# STM32N657 register map
File version: 1.0
CPU: CM55 r0p1, little endian, no MPU, FPU, vendor SysTick, 8 interrupt priority bits
Registers are 32-bit, read-write, reset 0x0 unless marked. A register's access mark holds for its fields unless they carry their own. Offsets are from the block's base; [hi:lo] are bit positions; {n}, {i} and the like mark numbered series.

## TIM1 — Advanced-control timers
Base 0x42000000
Same registers: TIM1_S 0x52000000
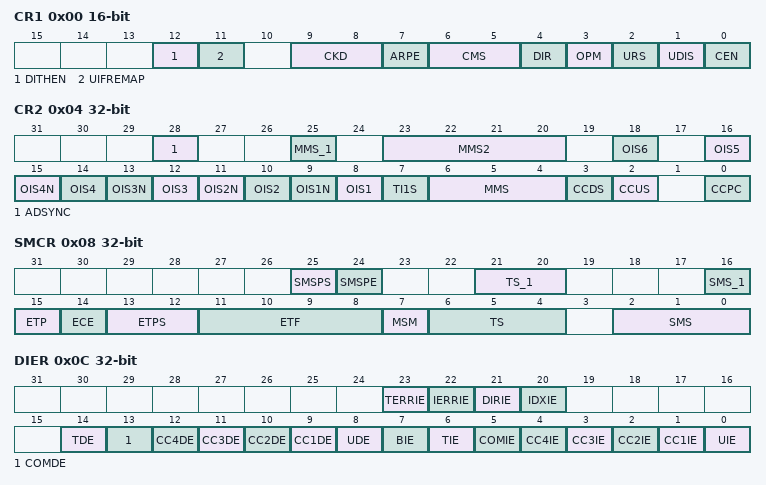
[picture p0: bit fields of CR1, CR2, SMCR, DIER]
0x00 CR1 16-bit — TIM1 control register 1
  [12] DITHEN — Dithering enable
  [11] UIFREMAP — UIF status bit remapping
  [9:8] CKD — Clock division
  [7] ARPE — Auto-reload preload enable
  [6:5] CMS — Center-aligned mode selection
  [4] DIR — Direction
  [3] OPM — One-pulse mode
  [2] URS — Update request source
  [1] UDIS — Update disable
  [0] CEN — Counter enable
0x04 CR2 — TIM1 control register 2
  [28] ADSYNC — ADC synchronization
  [25] MMS_1 — MMS[3]
  [23:20] MMS2 — Master mode selection 2
  [18] OIS6 — Output idle state 6 (tim_oc6 output)
  [16] OIS5 — Output idle state 5 (tim_oc5 output)
  [2n+7] OIS{n}N (n=1..4) — Output idle state {n} (tim_oc{n}n output)
  [14] OIS4 — Output idle state 4 (tim_oc4 output)
  [12] OIS3 — Output idle state 3 (tim_oc3n output)
  [10] OIS2 — Output idle state 2 (tim_oc2 output)
  [8] OIS1 — Output idle state 1 (tim_oc1 output)
  [7] TI1S — tim_ti1 selection
  [6:4] MMS — MMS[2:0]: Master mode selection
  [3] CCDS — Capture/compare DMA selection
  [2] CCUS — Capture/compare control update selection
  [0] CCPC — Capture/compare preloaded control
0x08 SMCR — TIM1 slave mode control register
  [25] SMSPS — SMS preload source
  [24] SMSPE — SMS preload enable
  [21:20] TS_1 — TS[4:3]
  [16] SMS_1 — SMS[3]
  [15] ETP — External trigger polarity
  [14] ECE — External clock enable
  [13:12] ETPS — External trigger prescaler
  [11:8] ETF — External trigger filter
  [7] MSM — Master/slave mode
  [6:4] TS — TS[2:0]: Trigger selection
  [2:0] SMS — SMS[2:0]: Slave mode selection
0x0C DIER — TIM1 DMA/interrupt enable register
  [23] TERRIE — Transition error interrupt enable
  [22] IERRIE — Index error interrupt enable
  [21] DIRIE — Direction change interrupt enable
  [20] IDXIE — Index interrupt enable
  [14] TDE — Trigger DMA request enable
  [13] COMDE — COM DMA request enable
  [n+8] CC{n}DE (n=1..4) — Capture/compare {n} DMA request enable
  [8] UDE — Update DMA request enable
  [7] BIE — Break interrupt enable
  [6] TIE — Trigger interrupt enable
  [5] COMIE — COM interrupt enable
  [n] CC{n}IE (n=1..4) — Capture/compare {n} interrupt enable
  [0] UIE — Update interrupt enable
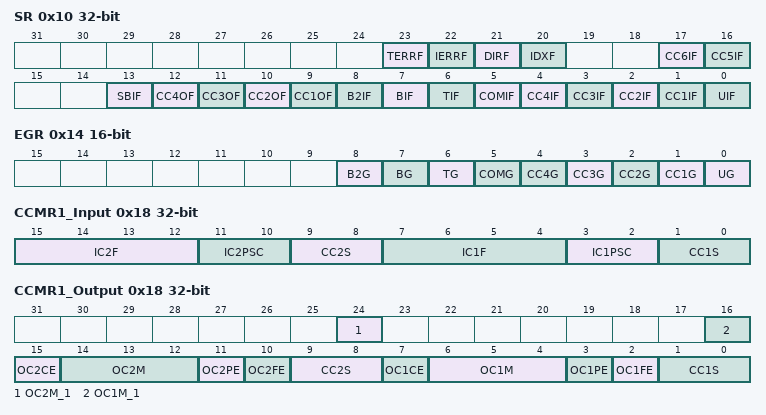
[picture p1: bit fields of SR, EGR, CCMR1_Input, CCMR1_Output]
0x10 SR — TIM1 status register
  [23] TERRF — Transition error interrupt flag
  [22] IERRF — Index error interrupt flag
  [21] DIRF — Direction change interrupt flag
  [20] IDXF — Index interrupt flag
  [17] CC6IF — Compare 6 interrupt flag
  [16] CC5IF — Compare 5 interrupt flag
  [13] SBIF — System break interrupt flag
  [n+8] CC{n}OF (n=1..4) — Capture/compare {n} overcapture flag
  [8] B2IF — Break 2 interrupt flag
  [7] BIF — Break interrupt flag
  [6] TIF — Trigger interrupt flag
  [5] COMIF — COM interrupt flag
  [n] CC{n}IF (n=1..4) — Capture/compare {n} interrupt flag
  [0] UIF — Update interrupt flag
0x14 EGR 16-bit wo — TIM1 event generation register
  [8] B2G — Break 2 generation
  [7] BG — Break generation
  [6] TG — Trigger generation
  [5] COMG — Capture/compare control update generation
  [n] CC{n}G (n=1..4) — Capture/compare {n} generation
  [0] UG — Update generation
0x18 CCMR1_Input — TIM1 capture/compare mode register 1 [alternate]
  [15:12] IC2F — Input capture 2 filter
  [11:10] IC2PSC — Input capture 2 prescaler
  [9:8] CC2S — Capture/compare 2 selection
  [7:4] IC1F — Input capture 1 filter
  [3:2] IC1PSC — Input capture 1 prescaler
  [1:0] CC1S — Capture/compare 1 Selection
0x18 CCMR1_Output (alternate view of CCMR1_Input) — TIM1 capture/compare mode register 1 [alternate]
  [24] OC2M_1 — OC2M[3]
  [16] OC1M_1 — OC1M[3]
  [15] OC2CE — Output compare 2 clear enable
  [14:12] OC2M — OC2M[2:0]: Output compare 2 mode
  [11] OC2PE — Output compare 2 preload enable
  [10] OC2FE — Output compare 2 fast enable
  [9:8] CC2S — Capture/compare 2 selection
  [7] OC1CE — Output compare 1 clear enable
  [6:4] OC1M — OC1M[2:0]: Output compare 1 mode
  [3] OC1PE — Output compare 1 preload enable
  [2] OC1FE — Output compare 1 fast enable
  [1:0] CC1S — Capture/compare 1 selection
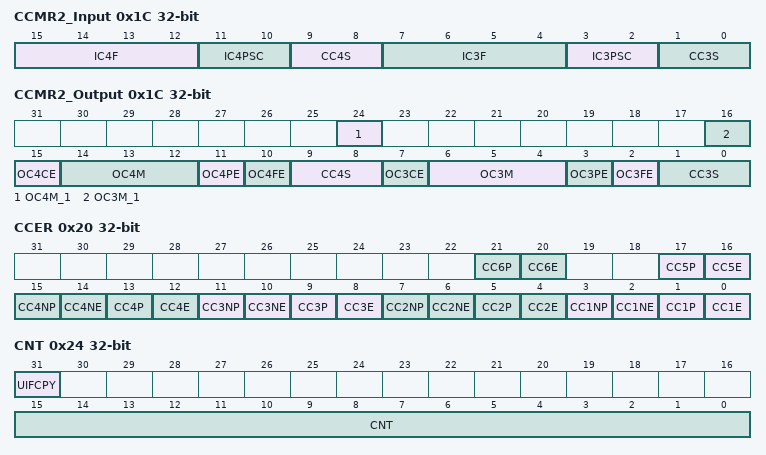
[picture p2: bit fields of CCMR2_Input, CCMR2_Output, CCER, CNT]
0x1C CCMR2_Input — TIM1 capture/compare mode register 2 [alternate]
  [15:12] IC4F — Input capture 4 filter
  [11:10] IC4PSC — Input capture 4 prescaler
  [9:8] CC4S — Capture/compare 4 selection
  [7:4] IC3F — Input capture 3 filter
  [3:2] IC3PSC — Input capture 3 prescaler
  [1:0] CC3S — Capture/compare 3 selection
0x1C CCMR2_Output (alternate view of CCMR2_Input) — TIM1 capture/compare mode register 2 [alternate]
  [24] OC4M_1 — OC4M[3]
  [16] OC3M_1 — OC3M[3]
  [15] OC4CE — Output compare 4 clear enable
  [14:12] OC4M — OC4M[2:0]: Output compare 4 mode
  [11] OC4PE — Output compare 4 preload enable
  [10] OC4FE — Output compare 4 fast enable
  [9:8] CC4S — Capture/compare 4 selection
  [7] OC3CE — Output compare 3 clear enable
  [6:4] OC3M — OC3M[2:0]: Output compare 3 mode
  [3] OC3PE — Output compare 3 preload enable
  [2] OC3FE — Output compare 3 fast enable
  [1:0] CC3S — Capture/compare 3 selection
0x20 CCER — TIM1 capture/compare enable register
  [4n-3] CC{n}P (n=1..6) — Capture/compare {n} output polarity
  [4n-4] CC{n}E (n=1..6) — Capture/compare {n} output enable
  [4n-1] CC{n}NP (n=1..4) — Capture/compare {n} complementary output polarity
  [4n-2] CC{n}NE (n=1..4) — Capture/compare {n} complementary output enable
0x24 CNT access per field — TIM1 counter
  [31] UIFCPY ro — UIF copy
  [15:0] CNT rw — Counter value
0x28 PSC 16-bit — TIM1 prescaler
  [15:0] PSC — Prescaler value
0x2C ARR reset 0xFFFF — TIM1 auto-reload register
  [19:0] ARR — Auto-reload value
0x30 RCR 16-bit — TIM1 repetition counter register
  [15:0] REP — Repetition counter reload value
0x34 CCR1 — TIM1 capture/compare register 1
  [19:0] CCR1 — Capture/compare 1 value
0x38 CCR2 — TIM1 capture/compare register 2
  [19:0] CCR2 — Capture/compare 2 value
0x3C CCR3 — TIM1 capture/compare register 3
  [19:0] CCR3 — Capture/compare value
0x40 CCR4 — TIM1 capture/compare register 4
  [19:0] CCR4 — Capture/compare value
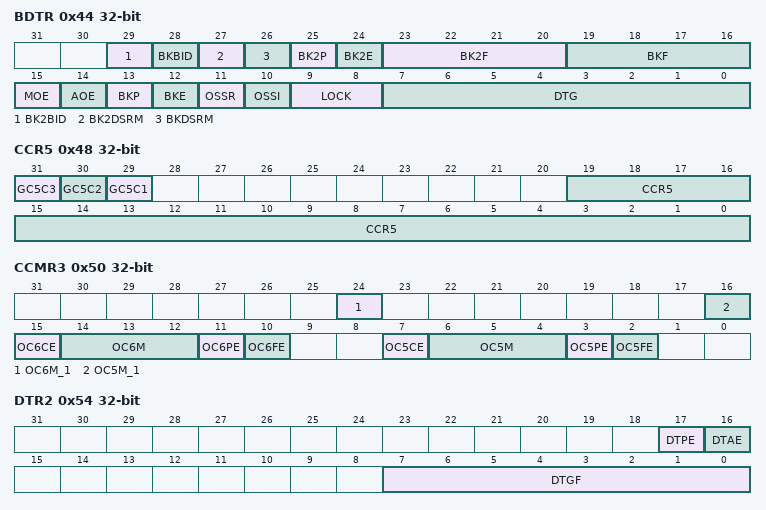
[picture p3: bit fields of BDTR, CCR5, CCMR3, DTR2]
0x44 BDTR — TIM1 break and dead-time register
  [29] BK2BID — Break2 bidirectional
  [28] BKBID — Break bidirectional
  [27] BK2DSRM — Break2 disarm
  [26] BKDSRM — Break disarm
  [25] BK2P — Break 2 polarity
  [24] BK2E — Break 2 enable
  [23:20] BK2F — Break 2 filter
  [19:16] BKF — Break filter
  [15] MOE — Main output enable
  [14] AOE — Automatic output enable
  [13] BKP — Break polarity
  [12] BKE — Break enable
  [11] OSSR — Off-state selection for Run mode
  [10] OSSI — Off-state selection for idle mode
  [9:8] LOCK — Lock configuration
  [7:0] DTG — Dead-time generator setup
0x48 CCR5 — TIM1 capture/compare register 5
  [31] GC5C3 — Group channel 5 and channel 3
  [30] GC5C2 — Group channel 5 and channel 2
  [29] GC5C1 — Group channel 5 and channel 1
  [19:0] CCR5 — Capture/compare 5 value
0x4C CCR6 — TIM1 capture/compare register 6
  [19:0] CCR6 — Capture/compare 6 value
0x50 CCMR3 — TIM1 capture/compare mode register 3
  [24] OC6M_1 — OC6M[3]
  [16] OC5M_1 — OC5M[3]
  [15] OC6CE — Output compare 6 clear enable
  [14:12] OC6M — OC6M[2:0]: Output compare 6 mode
  [11] OC6PE — Output compare 6 preload enable
  [10] OC6FE — Output compare 6 fast enable
  [7] OC5CE — Output compare 5 clear enable
  [6:4] OC5M — OC5M[2:0]: Output compare 5 mode
  [3] OC5PE — Output compare 5 preload enable
  [2] OC5FE — Output compare 5 fast enable
0x54 DTR2 — TIM1 timer deadtime register 2
  [17] DTPE — Deadtime preload enable
  [16] DTAE — Deadtime asymmetric enable
  [7:0] DTGF — Dead-time falling edge generator setup
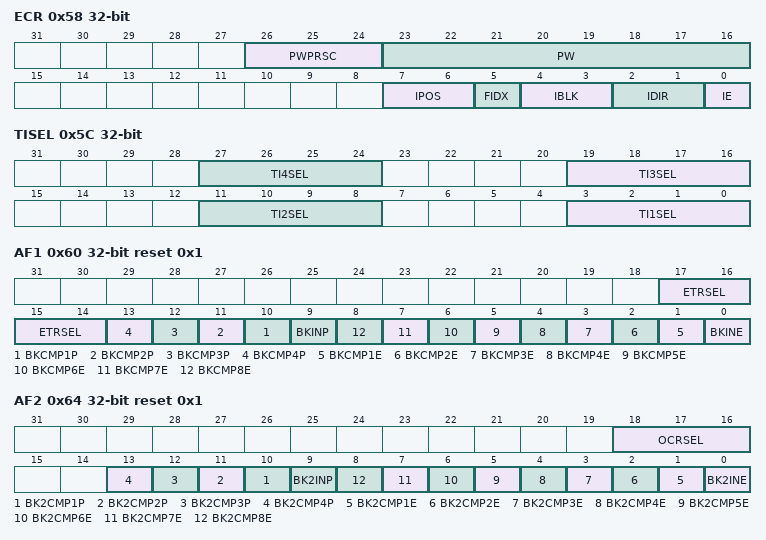
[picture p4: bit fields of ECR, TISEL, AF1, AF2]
0x58 ECR — TIM1 timer encoder control register
  [26:24] PWPRSC — Pulse width prescaler
  [23:16] PW — Pulse width
  [7:6] IPOS — Index positioning
  [5] FIDX — First index
  [4:3] IBLK — Index blanking
  [2:1] IDIR — Index direction
  [0] IE — Index enable
0x5C TISEL — TIM1 timer input selection register
  [8n-5:8n-8] TI{n}SEL (n=1..4) — Selects tim_ti{n}[15:0] input
0x60 AF1 reset 0x1 — TIM1 alternate function option register 1
  [17:14] ETRSEL — etr_in source selection
  [n+9] BKCMP{n}P (n=1..4) — tim_brk_cmp{n} input polarity
  [9] BKINP — TIMx_BKIN input polarity
  [n] BKCMP{n}E (n=1..8) — tim_brk_cmp{n} enable
  [0] BKINE — TIMx_BKIN input enable
0x64 AF2 reset 0x1 — TIM1 alternate function register 2
  [18:16] OCRSEL — ocref_clr source selection
  [n+9] BK2CMP{n}P (n=1..4) — tim_brk2_cmp{n} input polarity
  [9] BK2INP — TIMx_BKIN2 input polarity
  [n] BK2CMP{n}E (n=1..8) — tim_brk2_cmp{n} enable
  [0] BK2INE — TIMx_BKIN2 input enable
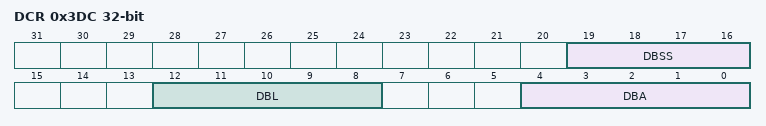
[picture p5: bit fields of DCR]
0x3DC DCR — TIM1 DMA control register
  [19:16] DBSS — DMA burst source selection
  [12:8] DBL — DMA burst length
  [4:0] DBA — DMA base address
0x3E0 DMAR — TIM1 DMA address for full transfer
  [31:0] DMAB — DMA register for burst accesses

## TIM8 — Advanced-control timers
Base 0x42000400
Same registers: TIM8_S 0x52000400
Registers as TIM1 (with TIM1 read as TIM8).
